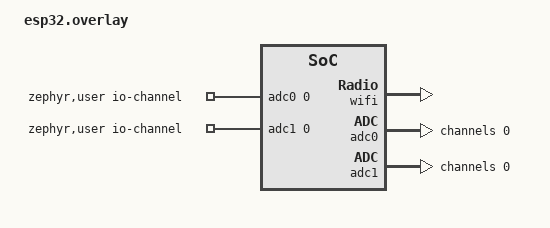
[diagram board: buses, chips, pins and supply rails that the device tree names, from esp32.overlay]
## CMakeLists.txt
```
# SPDX-License-Identifier: Apache-2.0

cmake_minimum_required(VERSION 3.20.0)
find_package(Zephyr REQUIRED HINTS $ENV{ZEPHYR_BASE})
project(smart_parking_demo)

FILE(GLOB app_sources src/*.cpp)
target_sources(app PRIVATE ${app_sources})
```

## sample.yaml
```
sample:
  name: Demo for Smart Parking Sensor
```

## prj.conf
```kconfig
CONFIG_STDOUT_CONSOLE=y
CONFIG_PRINTK=y

# Use DHCP for IPv4
CONFIG_NET_DHCPV4=y
CONFIG_NET_CONFIG_AUTO_INIT=y

CONFIG_I2C=y
CONFIG_ADC=y

CONFIG_WIFI=y
CONFIG_WIFI_ESP32=y
#CONFIG_HEAP_MEM_POOL_SIZE=96304
CONFIG_INIT_STACKS=y

CONFIG_NET_ARP=y

CONFIG_NETWORKING=y
CONFIG_NET_IPV4=y
CONFIG_NET_IPV6=n
CONFIG_NET_TCP=y

#UDP enabled to fix: [error: 'struct net_if_config' has no member named 'dhcpv4']
CONFIG_NET_UDP=y
#CONFIG_DNS_RESOLVER=y
#CONFIG_DNS_RESOLVER_AI_MAX_ENTRIES=10
CONFIG_NET_SOCKETS=y
#CONFIG_HTTP_CLIENT=y
CONFIG_NET_SOCKETS_POSIX_NAMES=y
CONFIG_NET_SOCKETS_POLL_MAX=4
CONFIG_NET_CONNECTION_MANAGER=y

CONFIG_NET_STATISTICS=y
CONFIG_NET_STATISTICS_PERIODIC_OUTPUT=y


## Or assign a static IP address (useful for testing)
## Following line must be enabled, otherwise WiFi connection fails with -1.
CONFIG_NET_CONFIG_SETTINGS=y
#
#

# Enabling logging can be helpful for debugging
CONFIG_NET_LOG=y
CONFIG_NET_SHELL=n
CONFIG_WIFI_LOG_LEVEL_ERR=y


CONFIG_NET_TX_STACK_SIZE=2048
CONFIG_NET_RX_STACK_SIZE=2048

CONFIG_NET_PKT_RX_COUNT=10
CONFIG_NET_PKT_TX_COUNT=10

CONFIG_NET_BUF_RX_COUNT=20
CONFIG_NET_BUF_TX_COUNT=20

CONFIG_NET_MAX_CONTEXTS=10

# Added to prevent error with missing #include <ethernet/eth_stats.h> for esp_wifi_drv.c
# Adding this line will cause CMAKE Warning: No SOURCES given to Zephyr library: drivers__ethernet
# Just ignore.
CONFIG_NET_L2_ETHERNET=y


CONFIG_NET_MGMT=n
CONFIG_NET_MGMT_EVENT=n
CONFIG_NET_MGMT_EVENT_INFO=n
CONFIG_NET_DEBUG_MGMT_EVENT_STACK=n
CONFIG_NET_L2_WIFI_MGMT=n
CONFIG_NET_STATISTICS_WIFI=n

#Net application
CONFIG_NET_TCP=y
CONFIG_NET_IPV4=y
CONFIG_NET_LOG=n
CONFIG_NET_STATISTICS=n






#
#
#
#CONFIG_EARLY_CONSOLE=y
#
#CONFIG_NETWORKING=y
#CONFIG_TEST_RANDOM_GENERATOR=y
#
#CONFIG_NET_TX_STACK_SIZE=2048
#CONFIG_NET_RX_STACK_SIZE=2048
#
#CONFIG_NET_PKT_RX_COUNT=10
#CONFIG_NET_PKT_TX_COUNT=10
#CONFIG_NET_BUF_RX_COUNT=20
#CONFIG_NET_BUF_TX_COUNT=20
#CONFIG_NET_MAX_CONTEXTS=10
#CONFIG_NET_DHCPV4=y
#
#CONFIG_NET_IPV4=y
#CONFIG_NET_IPV6=n
#
#CONFIG_NET_TCP=y
#
#CONFIG_NET_LOG=y
#CONFIG_INIT_STACKS=y
#
#CONFIG_NET_SHELL=y
#
#CONFIG_NET_STATISTICS=y
#CONFIG_NET_STATISTICS_PERIODIC_OUTPUT=n
#
#CONFIG_WIFI=y
#CONFIG_WIFI_LOG_LEVEL_ERR=y
#CONFIG_NET_L2_WIFI_SHELL=y



CONFIG_NETWORKING=y
CONFIG_NET_IPV4=y
CONFIG_NET_ARP=y
CONFIG_NET_DHCPV4=y

#CONFIG_TEST_RANDOM_GENERATOR=y

CONFIG_LOG=y

CONFIG_SLIP_STATISTICS=n
#CONFIG_NET_SHELL=y


#cpp
CONFIG_CPP=y
CONFIG_CPLUSPLUS=y
CONFIG_LIB_CPLUSPLUS=y
#CONFIG_CPP_MAIN=y
#CONFIG_GLIBCXX_LIBCPP=y
#CONFIG_LIBCPP_IMPLEMENTATION=y

#SNTP
CONFIG_SNTP=y
#CONFIG_POSIX_API=y

CONFIG_MAIN_STACK_SIZE=2048

# debug
```

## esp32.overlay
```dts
/*
 * Copyright (c) 2022 Wolter HV <wolterhv@gmx.de>
 *
 * SPDX-License-Identifier: Apache-2.0
 */

&wifi {
	status = "okay";
};

/ {
	zephyr,user {
		io-channels =
			<&adc0 0>,
			<&adc1 0>;
	};
};

&adc0 {
	status = "okay";
	#address-cells = <1>;
	#size-cells = <0>;

	channel@0 {
		reg = <0>;
		zephyr,gain = "ADC_GAIN_1_4";
		zephyr,reference = "ADC_REF_INTERNAL";
		zephyr,acquisition-time = <ADC_ACQ_TIME_DEFAULT>;
		zephyr,resolution = <12>;
	};
};

&adc1 {
	status = "okay";
	#address-cells = <1>;
	#size-cells = <0>;

	channel@0 {
		reg = <0>;
		zephyr,gain = "ADC_GAIN_1_4";
		zephyr,reference = "ADC_REF_INTERNAL";
		zephyr,acquisition-time = <ADC_ACQ_TIME_DEFAULT>;
		zephyr,resolution = <12>;
	};
};
```

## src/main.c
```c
/*
 * Copyright (c) 2015 Intel Corporation
 *
 * SPDX-License-Identifier: Apache-2.0
 */

#include <errno.h>
#include <zephyr/kernel.h>
#include <zephyr/sys/printk.h>
#include <zephyr/device.h>
#include <zephyr/drivers/i2c.h>

// WiFi stuff
#include <zephyr/net/net_mgmt.h>
#include <zephyr/net/net_if.h>
#include <zephyr/net/wifi_mgmt.h>
#include <zephyr/net/net_event.h>

// TCP
#include <zephyr/net/net_ip.h>
#include <zephyr/net/socket.h>
#include <zephyr/net/websocket.h>

//
#include "hmc_5883l_driver_port.h"

static bool flagIP = false;


/**
 * 
 * Socket stuff
*/

static int setup_socket(sa_family_t family, const char *server, int port,
			int *sock, struct sockaddr *addr, socklen_t addr_len)
{
	const char *family_str = "IPv4";
	int ret = 0;

	memset(addr, 0, addr_len);

    net_sin(addr)->sin_family = AF_INET;
    net_sin(addr)->sin_port = htons(port);
    inet_pton(AF_INET, server, &net_sin(addr)->sin_addr);

    *sock = socket(AF_INET, SOCK_STREAM, IPPROTO_TCP);

	if (*sock < 0) {
		printk("Failed to create %s HTTP socket (%d)", family_str,
			-errno);
	}
    else
    {
        printk("Socket successfully created.\n");
    }

	return ret;
}

static int connect_socket(sa_family_t family, const char *server, int port,
			  int *sock, struct sockaddr *addr, socklen_t addr_len)
{
	int ret;

	ret = setup_socket(family, server, port, sock, addr, addr_len);
	if (ret < 0 || *sock < 0) {
		return -1;
	}

    printk("Connecting...\n");
	ret = connect(*sock, addr, addr_len);
    printk("Done!\n");
	if (ret < 0) {
		printk("Cannot connect to %s remote (%d)\n",
			"IPv4",
			-errno);
		ret = -errno;
	}
    else
    {
        printk("Socket connected.\n");
    }

	return ret;
}

static int connect_cb(int sock, struct http_request *req, void *user_data)
{
	printk("Websocket %d for %s connected.", sock, (char *)user_data);

	return 0;
}


/**
 * @file Sample app using the Fujitsu MB85RC256V FRAM through I2C.
 */

/* Macros ========================================================*/
/* WiFi parameters */
#define AP_SSID_ "Funeswifi"
#define AP_PSK_ "00435763252"

/* size of stack area used by each thread */
#define STACKSIZE 1024

/* scheduling priority used by each thread */
#define PRIORITY 7

/* Private functions =============================================*/
static K_SEM_DEFINE(wifi_connected, 0, 1);
static K_SEM_DEFINE(ipv4_address_obtained, 0, 1);

static struct net_mgmt_event_callback wifi_cb;
static struct net_mgmt_event_callback ipv4_cb;

static void handle_wifi_connect_result(struct net_mgmt_event_callback *cb)
{
    const struct wifi_status *status = (const struct wifi_status *)cb->info;

    if (status->status)
    {
        printk("Connection request failed (%d)\n", status->status);
    }
    else
    {
        printk("Connected\n");
        //k_sem_give(&wifi_connected);
    }
}

static void handle_wifi_disconnect_result(struct net_mgmt_event_callback *cb)
{
    const struct wifi_status *status = (const struct wifi_status *)cb->info;

    if (status->status)
    {
        printk("Disconnection request (%d)\n", status->status);
    }
}

static void handle_ipv4_result(struct net_if *iface)
{
    int i = 0;

    for (i = 0; i < NET_IF_MAX_IPV4_ADDR; i++) {

        char buf[NET_IPV4_ADDR_LEN];

        if (iface->config.ip.ipv4->unicast[i].addr_type != NET_ADDR_DHCP) {
            continue;
        }

        printk("IPv4 address: %s\n",
                net_addr_ntop(AF_INET,
                                &iface->config.ip.ipv4->unicast[i].address.in_addr,
                                buf, sizeof(buf)));
        printk("Subnet: %s\n",
                net_addr_ntop(AF_INET,
                                &iface->config.ip.ipv4->netmask,
                                buf, sizeof(buf)));
        printk("Router: %s\n",
                net_addr_ntop(AF_INET,
                                &iface->config.ip.ipv4->gw,
                                buf, sizeof(buf)));
        }

        //k_sem_give(&ipv4_address_obtained);
        flagIP = true;
}

static void wifi_mgmt_event_handler(struct net_mgmt_event_callback *cb, uint32_t mgmt_event, struct net_if *iface)
{
    switch (mgmt_event)
    {

        case NET_EVENT_WIFI_CONNECT_RESULT:
            printk("Received NET_EVENT_WIFI_CONNECT_RESULT.\n");
            handle_wifi_connect_result(cb);
            break;

        case NET_EVENT_WIFI_DISCONNECT_RESULT:
            printk("Received NET_EVENT_WIFI_DISCONNECT_RESULT.\n");
            handle_wifi_disconnect_result(cb);
            break;

        case NET_EVENT_IPV4_ADDR_ADD:
            printk("Received NET_EVENT_IPV4_ADDR_ADD.\n");
            handle_ipv4_result(iface);
            break;

        default:
            break;
    }
}

void wifi_connect(void)
{
    struct net_if *iface = net_if_get_default();

    struct wifi_connect_req_params wifi_params = {0};

    wifi_params.ssid = AP_SSID_;
    wifi_params.psk = AP_PSK_;
    wifi_params.ssid_length = strlen(AP_SSID_);
    wifi_params.psk_length = strlen(AP_PSK_);
    wifi_params.channel = WIFI_CHANNEL_ANY;
    wifi_params.security = WIFI_SECURITY_TYPE_PSK;
    wifi_params.band = WIFI_FREQ_BAND_2_4_GHZ; 
    wifi_params.mfp = WIFI_MFP_DISABLE;
    wifi_params.timeout = SYS_FOREVER_MS;

    printk("Connecting to SSID: %s\n", wifi_params.ssid);

    if (net_mgmt(NET_REQUEST_WIFI_AP_DISABLE, iface, &wifi_params, sizeof(struct wifi_connect_req_params)))
    {
       printk("WiFi in AP Mode Disable Error.\n");
    }
    else
    {
       printk("WiFi in AP Mode Disable.\n");
    }

    if (net_mgmt(NET_REQUEST_WIFI_SCAN, iface, &wifi_params, sizeof(struct wifi_connect_req_params)))
    {
       printk("WiFi Scan Request Error.\n");
    }
    else
    {
       printk("WiFi Scan Request Done!.\n");
    }

    if (net_mgmt_event_wait_on_iface(iface, NET_EVENT_WIFI_SCAN_RESULT, NULL, NULL, NULL, K_FOREVER))
        printk("Scan done!\n");

    if (net_mgmt(NET_REQUEST_WIFI_CONNECT, iface, &wifi_params, sizeof(struct wifi_connect_req_params)))
    {
        printk("WiFi Connection Request Failed\n");
    }
	else
	{
		printk("WiFi Connection Request success.\n");
	}

#if 0
    if (net_mgmt_event_wait_on_iface(iface, NET_EVENT_WIFI_CONNECT_RESULT, NULL, NULL, NULL, K_FOREVER))
        printk("WiFi connected.\n");
#endif
}

void wifi_status(void)
{
    struct net_if *iface = net_if_get_default();

    struct wifi_iface_status status = {0};

    if (net_mgmt(NET_REQUEST_WIFI_IFACE_STATUS, iface, &status,	sizeof(struct wifi_iface_status)))
    {
        printk("WiFi Status Request Failed\n");
    }
    else
    {
        printk("WiFi Status Request Success.\n");
    }

    printk("\n");

    if (status.state >= WIFI_STATE_ASSOCIATED) {
        printk("SSID: %-32s\n", status.ssid);
        printk("Band: %s\n", wifi_band_txt(status.band));
        printk("Channel: %d\n", status.channel);
        printk("Security: %s\n", wifi_security_txt(status.security));
        printk("RSSI: %d\n", status.rssi);
    }
}

void wifi_disconnect(void)
{
    struct net_if *iface = net_if_get_default();

    if (net_mgmt(NET_REQUEST_WIFI_DISCONNECT, iface, NULL, 0))
    {
        printk("WiFi Disconnection Request Failed\n");
    }
}
/* Threads =======================================================*/

static void hmc_thread(void)
{
	const struct device *const i2c_dev = DEVICE_DT_GET(DT_NODELABEL(i2c0));
    hmc_5883l_driver_t hmc_driver;
	uint8_t hmc_buf[20];
	uint8_t ret;
	uint8_t command[2] = {0x06, 0x03};

    // Driver initialization
    hmc_5883l_driverInitPort(&hmc_driver, i2c_dev);
	hmc_configureContinuosMode(&hmc_driver);

	for(;;)
	{
		int16_t xx, yy, zz;
		uint8_t cmd;
		k_msleep(100);

		cmd=3;
		ret = hmc_driver.write(&hmc_driver, &cmd, 1);
		if (ret)
			printk("Error on write Mode.");
		ret = hmc_driver.read(&hmc_driver, &hmc_buf[3], 3);
		if (ret)
			printk("Error on write 1st command.\r\n");
		cmd=6;
		ret = hmc_driver.write(&hmc_driver, &cmd, 1);
		if (ret)
			printk("Error on write Mode.");
		ret = hmc_driver.read(&hmc_driver, &hmc_buf[6], 3);
		if (ret)
			printk("Error on write 1st command.\r\n");
		cmd=9;
		ret = hmc_driver.write(&hmc_driver, &cmd, 1);
		if (ret)
			printk("Error on write Mode.");
		ret = hmc_driver.read(&hmc_driver, &hmc_buf[9], 4);
		if (ret)
			printk("Error on write 1st command.\r\n");

		xx = hmc_buf[3] << 8 | hmc_buf[4];
		zz = hmc_buf[5] << 8 | hmc_buf[6];
		yy = hmc_buf[7] << 8 | hmc_buf[8];

		printk("x:(%i) y:(%i) z:(%i) status:(%x)\r\n", xx, yy, zz, hmc_buf[9]);
		printk("idA:(%x) idB:(%x) idC:(%x)", hmc_buf[10], hmc_buf[11], hmc_buf[12]);
	}

#if 0
	hmc_buf[0] = 9;
	ret = hmc_driver.write(&hmc_driver, hmc_buf, 1);
	if (ret)
	{
		printk("Error on 1st write.");
	}

	ret = hmc_driver.read(&hmc_driver, hmc_buf, 4);
	if (ret)
	{
		printk("Error on 1st write.");
	}
	else
	{
		printk("Successfully read all bytes:\r\n");
		for( uint8_t i=0; i<4; ++i)
		{
			printk("field[%d]: (0x%x)\r\n", i, hmc_buf[i]);
		}
	}
#endif
}

static struct net_mgmt_event_callback mgmt_cb;

static void handler(struct net_mgmt_event_callback *cb,
		    uint32_t mgmt_event,
		    struct net_if *iface)
{
	int i = 0;

	if (mgmt_event != NET_EVENT_IPV4_ADDR_ADD) {
		return;
	}

	for (i = 0; i < NET_IF_MAX_IPV4_ADDR; i++) {
		char buf[NET_IPV4_ADDR_LEN];

		if (iface->config.ip.ipv4->unicast[i].addr_type !=
							NET_ADDR_DHCP) {
			continue;
		}

		printk("Your address: %s",
			net_addr_ntop(AF_INET,
			    &iface->config.ip.ipv4->unicast[i].address.in_addr,
						  buf, sizeof(buf)));
		printk("Lease time: %u seconds",
			 iface->config.dhcpv4.lease_time);
		printk("Subnet: %s",
			net_addr_ntop(AF_INET,
				       &iface->config.ip.ipv4->netmask,
				       buf, sizeof(buf)));
		printk("Router: %s",
			net_addr_ntop(AF_INET,
						 &iface->config.ip.ipv4->gw,
						 buf, sizeof(buf)));
	}
}


void main(void)
{
	int sock;

    printk("WiFi Example\n\n");

    net_mgmt_init_event_callback(&wifi_cb, wifi_mgmt_event_handler,
                                 NET_EVENT_WIFI_CONNECT_RESULT | NET_EVENT_WIFI_DISCONNECT_RESULT);

    net_mgmt_init_event_callback(&ipv4_cb, wifi_mgmt_event_handler, NET_EVENT_IPV4_ADDR_ADD);

    net_mgmt_add_event_callback(&wifi_cb);
    net_mgmt_add_event_callback(&ipv4_cb);
    printk("Callbacks set.\n");

    k_sleep(K_SECONDS(2)); 
    wifi_connect();
    printk("Connection Done...\n");
    //k_sem_take(&wifi_connected, K_FOREVER);
    printk("2Connection Done...\n");
    //k_sem_take(&ipv4_address_obtained, K_FOREVER);
    printk("Ready...\n\n");

    while(!flagIP) k_sleep(K_SECONDS(1));

	#if 0
    printk("Looking up IP addresses:\n");
    struct zsock_addrinfo *res;
    nslookup("iot.beyondlogic.org", &res);
    print_addrinfo_results(&res);

    printk("Connecting to HTTP Server:\n");
    sock = connect_socket(&res);
    http_get(sock, "iot.beyondlogic.org", "/test.txt");
    zsock_close(sock);
    
    wifi_connect();
    // Stay connected for 30 seconds, then disconnect.
	#endif

    while(1)
    {
        // Socket stuff

        int sock4 = -1;
        int websock4 = -1;
        struct sockaddr_in addr4;
        size_t amount;
        int ret;

        (void)connect_socket(AF_INET, "169.55.61.243", 9012,
                        &sock4, (struct sockaddr *)&addr4,
                        sizeof(addr4));
        if (sock4 < 0) {
            printk("Cannot create HTTP connection.");
        }
        else
        {
            printk("Connection created.\n");

            printk("Sending...\n");

            char data[] = "ESP32/1.0|POST|BBFF-DQaxQtnjWZzKDzTsVRtOUfNLulXxqf|64a2425cbe387b5d626506e1:pythonTestDevice=>fieldX:20.2|end";

            int rc = send(sock4, data, strlen(data), 0);

            printk("Data sent!\n");
            
            if (rc < 0)
                printk("Error sending.\n");
            
            close(sock4);
        }

        k_sleep(K_MINUTES(10));
    }
#if 0
    wifi_disconnect();
    while(1)
    {
        printk("Looping...\r\n");
        k_sleep(K_SECONDS(5)); 
        wifi_status();
    }
    #endif
}

#if 0
K_THREAD_DEFINE(hmc_id, STACKSIZE, hmc_thread, NULL, NULL, NULL,
		PRIORITY, 0, 0);
        #endif
```

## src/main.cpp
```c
/*
 * Copyright (c) 2015 Intel Corporation
 *
 * SPDX-License-Identifier: Apache-2.0
 */
#include <errno.h>
#include <zephyr/kernel.h>
#include <zephyr/sys/printk.h>
#include <zephyr/device.h>
#include <zephyr/drivers/i2c.h>
#include <zephyr/drivers/adc.h>

// WiFi stuff
#include <zephyr/net/net_mgmt.h>
#include <zephyr/net/net_if.h>
#include <zephyr/net/wifi_mgmt.h>
#include <zephyr/net/net_event.h>

// TCP
#include <zephyr/net/net_ip.h>
#include <zephyr/net/socket.h>
#include <zephyr/net/websocket.h>
#include "esp_sleep.h"

// SNTP
#include <zephyr/net/sntp.h>
#ifdef CONFIG_POSIX_API
#include <arpa/inet.h>
#endif

#include <zephyr/posix/time.h>

//
#include "hmc_5883l_driver_port.h"

// CPP
#include <iostream>
#include <string>

// Power Management
#include <zephyr/pm/pm.h>
#include <zephyr/pm/device.h>
#include <zephyr/pm/policy.h>

static bool flagIP = false;

struct hmc_values_s
{
   int x;
   int y;
   int z;
   int sample = 123; 
};

typedef struct hmc_values_s hmc_values_t;
static hmc_values_t hmc_values;

K_SEM_DEFINE(hmc_sem, 0, K_SEM_MAX_LIMIT);
K_SEM_DEFINE(wifi_sem, 0, K_SEM_MAX_LIMIT);


/**
 * 
 * Socket stuff
*/

static int setup_socket(sa_family_t family, const char *server, int port,
			int *sock, struct sockaddr *addr, socklen_t addr_len)
{
	const char *family_str = "IPv4";
	int ret = 0;

	memset(addr, 0, addr_len);

    net_sin(addr)->sin_family = AF_INET;
    net_sin(addr)->sin_port = htons(port);
    inet_pton(AF_INET, server, &net_sin(addr)->sin_addr);

    *sock = socket(AF_INET, SOCK_STREAM, IPPROTO_TCP);

	if (*sock < 0) {
		printk("Failed to create %s HTTP socket (%d)", family_str,
			-errno);
	}
    else
    {
        printk("Socket successfully created.\n");
    }

	return ret;
}

static int connect_socket(sa_family_t family, const char *server, int port,
			  int *sock, struct sockaddr *addr, socklen_t addr_len)
{
	int ret;

	ret = setup_socket(family, server, port, sock, addr, addr_len);
	if (ret < 0 || *sock < 0) {
		return -1;
	}

    printk("Connecting...\n");
	ret = connect(*sock, addr, addr_len);
    printk("Done!\n");
	if (ret < 0) {
		printk("Cannot connect to %s remote (%d)\n",
			"IPv4",
			-errno);
		ret = -errno;
	}
    else
    {
        printk("Socket connected.\n");
    }

	return ret;
}

static int connect_cb(int sock, struct http_request *req, void *user_data)
{
	printk("Websocket %d for %s connected.", sock, (char *)user_data);

	return 0;
}


/**
 * @file Sample app using the Fujitsu MB85RC256V FRAM through I2C.
 */

/* Macros ========================================================*/
/* WiFi parameters */
#define AP_SSID_ "Funeswifi"
#define AP_PSK_ "00435763252"

/* size of stack area used by each thread */
#define STACKSIZE 2048

/* scheduling priority used by each thread */
#define PRIORITY 7

/* Private functions =============================================*/
static K_SEM_DEFINE(wifi_connected, 0, 1);
static K_SEM_DEFINE(ipv4_address_obtained, 0, 1);

static struct net_mgmt_event_callback wifi_cb;
static struct net_mgmt_event_callback ipv4_cb;

static void handle_wifi_connect_result(struct net_mgmt_event_callback *cb)
{
    const struct wifi_status *status = (const struct wifi_status *)cb->info;

    if (status->status)
    {
        printk("Connection request failed (%d)\n", status->status);
    }
    else
    {
        printk("Connected\n");
        //k_sem_give(&wifi_connected);
    }
}

static void handle_wifi_disconnect_result(struct net_mgmt_event_callback *cb)
{
    const struct wifi_status *status = (const struct wifi_status *)cb->info;

    if (status->status)
    {
        printk("Disconnection request (%d)\n", status->status);
    }
}

static void handle_ipv4_result(struct net_if *iface)
{
    int i = 0;

    for (i = 0; i < NET_IF_MAX_IPV4_ADDR; i++) {

        char buf[NET_IPV4_ADDR_LEN];

        if (iface->config.ip.ipv4->unicast[i].addr_type != NET_ADDR_DHCP) {
            continue;
        }

        printk("IPv4 address: %s\n",
                net_addr_ntop(AF_INET,
                                &iface->config.ip.ipv4->unicast[i].address.in_addr,
                                buf, sizeof(buf)));
        printk("Subnet: %s\n",
                net_addr_ntop(AF_INET,
                                &iface->config.ip.ipv4->netmask,
                                buf, sizeof(buf)));
        printk("Router: %s\n",
                net_addr_ntop(AF_INET,
                                &iface->config.ip.ipv4->gw,
                                buf, sizeof(buf)));
        }

        //k_sem_give(&ipv4_address_obtained);
        flagIP = true;
}

static void wifi_mgmt_event_handler(struct net_mgmt_event_callback *cb, uint32_t mgmt_event, struct net_if *iface)
{
    switch (mgmt_event)
    {

        case NET_EVENT_WIFI_CONNECT_RESULT:
            printk("Received NET_EVENT_WIFI_CONNECT_RESULT.\n");
            handle_wifi_connect_result(cb);
            break;

        case NET_EVENT_WIFI_DISCONNECT_RESULT:
            printk("Received NET_EVENT_WIFI_DISCONNECT_RESULT.\n");
            handle_wifi_disconnect_result(cb);
            break;

        case NET_EVENT_IPV4_ADDR_ADD:
            printk("Received NET_EVENT_IPV4_ADDR_ADD.\n");
            handle_ipv4_result(iface);
            break;

        default:
            break;
    }
}

void wifi_connect(void)
{
    struct net_if *iface = net_if_get_default();

    struct wifi_connect_req_params wifi_params = {0};

    wifi_params.ssid = reinterpret_cast<uint8_t *>(const_cast<char*>(AP_SSID_));
    wifi_params.psk = reinterpret_cast<uint8_t*>(const_cast<char*>(AP_PSK_));
    wifi_params.ssid_length = strlen(AP_SSID_);
    wifi_params.psk_length = strlen(AP_PSK_);
    wifi_params.channel = WIFI_CHANNEL_ANY;
    wifi_params.security = WIFI_SECURITY_TYPE_PSK;
    wifi_params.band = WIFI_FREQ_BAND_2_4_GHZ; 
    wifi_params.mfp = WIFI_MFP_DISABLE;
    wifi_params.timeout = SYS_FOREVER_MS;

    printk("Connecting to SSID: %s\n", wifi_params.ssid);

    if (net_mgmt(NET_REQUEST_WIFI_AP_DISABLE, iface, &wifi_params, sizeof(struct wifi_connect_req_params)))
    {
       printk("WiFi in AP Mode Disable Error.\n");
    }
    else
    {
       printk("WiFi in AP Mode Disable.\n");
    }

    if (net_mgmt(NET_REQUEST_WIFI_SCAN, iface, &wifi_params, sizeof(struct wifi_connect_req_params)))
    {
       printk("WiFi Scan Request Error.\n");
    }
    else
    {
       printk("WiFi Scan Request Done!.\n");
    }

    if (net_mgmt_event_wait_on_iface(iface, NET_EVENT_WIFI_SCAN_RESULT, NULL, NULL, NULL, K_FOREVER))
        printk("Scan done!\n");

    if (net_mgmt(NET_REQUEST_WIFI_CONNECT, iface, &wifi_params, sizeof(struct wifi_connect_req_params)))
    {
        printk("WiFi Connection Request Failed\n");
    }
	else
	{
		printk("WiFi Connection Request success.\n");
	}

#if 0
    if (net_mgmt_event_wait_on_iface(iface, NET_EVENT_WIFI_CONNECT_RESULT, NULL, NULL, NULL, K_FOREVER))
        printk("WiFi connected.\n");
#endif
}

void wifi_status(void)
{
    struct net_if *iface = net_if_get_default();

    struct wifi_iface_status status = {0};

    if (net_mgmt(NET_REQUEST_WIFI_IFACE_STATUS, iface, &status,	sizeof(struct wifi_iface_status)))
    {
        printk("WiFi Status Request Failed\n");
    }
    else
    {
        printk("WiFi Status Request Success.\n");
    }

    printk("\n");

    if (status.state >= WIFI_STATE_ASSOCIATED) {
        printk("SSID: %-32s\n", status.ssid);
        printk("Band: %s\n", wifi_band_txt(status.band));
        printk("Channel: %d\n", status.channel);
        printk("Security: %s\n", wifi_security_txt(status.security));
        printk("RSSI: %d\n", status.rssi);
    }
}

void wifi_disconnect(void)
{
    struct net_if *iface = net_if_get_default();

    if (net_mgmt(NET_REQUEST_WIFI_DISCONNECT, iface, NULL, 0))
    {
        printk("WiFi Disconnection Request Failed\n");
    }
}
/* Threads =======================================================*/

extern "C"
{

static void hmc_thread(void)
{
    std::cout << "Running thread...\n";
	const struct device *const i2c_dev = DEVICE_DT_GET(DT_NODELABEL(i2c0));
    hmc_5883l_driver_t hmc_driver;
	uint8_t hmc_buf[20];
	uint8_t ret;
	uint8_t command[2] = {0x06, 0x03};


    // Driver initialization
    hmc_5883l_driverInitPort(&hmc_driver, i2c_dev);
	hmc_configureContinuosMode(&hmc_driver);

	for(;;)
	{
        std::cout << "hmc\r\n";
		int16_t xx, yy, zz;
		uint8_t cmd;
		k_msleep(100);

		cmd=3;
		ret = hmc_driver.write(&hmc_driver, &cmd, 1);
		if (ret)
			printk("Error on write Mode.");
		ret = hmc_driver.read(&hmc_driver, &hmc_buf[3], 3);
		if (ret)
			printk("Error on write 1st command.\r\n");
		cmd=6;
		ret = hmc_driver.write(&hmc_driver, &cmd, 1);
		if (ret)
			printk("Error on write Mode.");
		ret = hmc_driver.read(&hmc_driver, &hmc_buf[6], 3);
		if (ret)
			printk("Error on write 1st command.\r\n");
		cmd=9;
		ret = hmc_driver.write(&hmc_driver, &cmd, 1);
		if (ret)
			printk("Error on write Mode.");
		ret = hmc_driver.read(&hmc_driver, &hmc_buf[9], 4);
		if (ret)
			printk("Error on write 1st command.\r\n");

		xx = hmc_buf[3] << 8 | hmc_buf[4];
		zz = hmc_buf[5] << 8 | hmc_buf[6];
		yy = hmc_buf[7] << 8 | hmc_buf[8];

        hmc_values.x = xx;
        hmc_values.y = yy;
        hmc_values.z = zz;
        //k_sem_give(&hmc_sem);
  //      k_sem_take(&wifi_sem, K_FOREVER);

		//printk("x:(%i) y:(%i) z:(%i) status:(%x)\r\n", xx, yy, zz, hmc_buf[9]);
		//printk("idA:(%x) idB:(%x) idC:(%x)\r\n", hmc_buf[10], hmc_buf[11], hmc_buf[12]);
	}

#if 0
	hmc_buf[0] = 9;
	ret = hmc_driver.write(&hmc_driver, hmc_buf, 1);
	if (ret)
	{
		printk("Error on 1st write.");
	}

	ret = hmc_driver.read(&hmc_driver, hmc_buf, 4);
	if (ret)
	{
		printk("Error on 1st write.");
	}
	else
	{
		printk("Successfully read all bytes:\r\n");
		for( uint8_t i=0; i<4; ++i)
		{
			printk("field[%d]: (0x%x)\r\n", i, hmc_buf[i]);
		}
	}
#endif
}
}

static struct net_mgmt_event_callback mgmt_cb;

static void handler(struct net_mgmt_event_callback *cb,
		    uint32_t mgmt_event,
		    struct net_if *iface)
{
	int i = 0;

	if (mgmt_event != NET_EVENT_IPV4_ADDR_ADD) {
		return;
	}

	for (i = 0; i < NET_IF_MAX_IPV4_ADDR; i++) {
		char buf[NET_IPV4_ADDR_LEN];

		if (iface->config.ip.ipv4->unicast[i].addr_type !=
							NET_ADDR_DHCP) {
			continue;
		}

		printk("Your address: %s",
			net_addr_ntop(AF_INET,
			    &iface->config.ip.ipv4->unicast[i].address.in_addr,
						  buf, sizeof(buf)));
		printk("Lease time: %u seconds",
			 iface->config.dhcpv4.lease_time);
		printk("Subnet: %s",
			net_addr_ntop(AF_INET,
				       &iface->config.ip.ipv4->netmask,
				       buf, sizeof(buf)));
		printk("Router: %s",
			net_addr_ntop(AF_INET,
						 &iface->config.ip.ipv4->gw,
						 buf, sizeof(buf)));
	}
}

#define WAKEUP_TIME_SEC		(20)

int main(void)
{
    return 0;
}

void wifi_thread(void)
{
    k_sleep(K_SECONDS(10)); 
	int sock;
    std::cout << "WiFi Example\n\n";

    net_mgmt_init_event_callback(&wifi_cb, wifi_mgmt_event_handler,
                                 NET_EVENT_WIFI_CONNECT_RESULT | NET_EVENT_WIFI_DISCONNECT_RESULT);

    net_mgmt_init_event_callback(&ipv4_cb, wifi_mgmt_event_handler, NET_EVENT_IPV4_ADDR_ADD);

    net_mgmt_add_event_callback(&wifi_cb);
    net_mgmt_add_event_callback(&ipv4_cb);
    std::cout << "Callbacks\n";

    k_sleep(K_SECONDS(2)); 
    wifi_connect();
    std::cout << "Ready...\n\n";

    while(!flagIP) k_sleep(K_SECONDS(1));

    //SNTP-----------------------
    struct sntp_ctx ctx;
    struct sockaddr_in addr;
    struct sntp_time sntp_time;
    int rv;
    struct timeval tv;
    struct timespec ts;

    /* ipv4 */
    memset(&addr, 0, sizeof(addr));
    addr.sin_family = AF_INET;
    addr.sin_port = htons(123);
    zsock_inet_pton(AF_INET, "170.210.222.10", &addr.sin_addr);

    rv = sntp_init(&ctx, (struct sockaddr *) &addr,
               sizeof(struct sockaddr_in));
    if (rv < 0) {
        std::cout << "Failed to init SNTP IPv4\r\n";
    }

    std::cout << "Sending SNTP IPv4 request...\r\n";
    rv = sntp_query(&ctx, 4 * MSEC_PER_SEC, &sntp_time);
    if (rv < 0) {
        std::cout << "SNTP IPv4 request failed: " << rv << "\r\n";
    }


    std::cout << "status: " << rv << "\r\n";
    printk("time since Epoch: high word: %u, low word: %u",
        (uint32_t)(sntp_time.seconds >> 32), (uint32_t)sntp_time.seconds);

    ts.tv_sec = sntp_time.seconds;

    //-----------------------SNTP


    while(1)
    {
        printk("WiFi\r\n\n");
        // Socket stuff
        int sock4 = -1;
        int websock4 = -1;
        struct sockaddr_in addr4;
        size_t amount;
        int ret;

        (void)connect_socket(AF_INET, "169.55.61.243", 9012,
                        &sock4, (struct sockaddr *)&addr4,
                        sizeof(addr4));
        if (sock4 < 0) {
            printk("Cannot create HTTP connection.");
        }
        else
        {
            printk("Connection created.\n");

            printk("Sending...\n");

            std::string log_str = "Logging from cpp.";
            printk("%s",log_str.c_str());

            std::cout << "Converting...\r\n";
            std::string xdata = "fieldX:" + std::to_string(hmc_values.x);
            std::string ydata = "fieldY:" + std::to_string(hmc_values.y);
            std::string zdata = "fieldZ:" + std::to_string(hmc_values.z);
            std::cout << "Convertion done!\r\n";
            std::string data = "ESP32/1.0|POST|BBFF-DQaxQtnjWZzKDzTsVRtOUfNLulXxqf|64a2425cbe387b5d626506e1:pythonTestDevice=>"+xdata+","+ydata+","+zdata+"|end";

            int rc = send(sock4, data.c_str(), strlen(data.c_str()), 0);

            printk("Data sent!\n");
            
            if (rc < 0)
                printk("Error sending.\n");

#if 1
            std::cout << "Converting...\r\n";
            std::string timestamp_str = "time: " + std::to_string(ts.tv_sec + k_uptime_get()/1000);
            std::cout << "Convertion Done\r\n";
            std::cout << timestamp_str << std::endl;
#endif
            
            close(sock4);
            //k_sem_give(&wifi_sem);
            //k_sem_take(&hmc_sem, K_FOREVER);
        }

        //k_sleep(K_MINUTES(1));
        k_sleep(K_SECONDS(5));
    }
#if 0
    wifi_disconnect();
    while(1)
    {
        printk("Looping...\r\n");
        k_sleep(K_SECONDS(5)); 
        wifi_status();
    }
    #endif
}

// ADC stuff ======================================

#define DT_SPEC_AND_COMMA(node_id, prop, idx) \
	ADC_DT_SPEC_GET_BY_IDX(node_id, idx),

/* Data of ADC io-channels specified in devicetree. */
static const struct adc_dt_spec adc_channels[] = {
	DT_FOREACH_PROP_ELEM(DT_PATH(zephyr_user), io_channels,
			     DT_SPEC_AND_COMMA)
};

void adc_thread(void)
{
	int err;
	uint32_t count = 0;
	uint16_t buf;
	struct adc_sequence sequence = {
		.buffer = &buf,
		/* buffer size in bytes, not number of samples */
		.buffer_size = sizeof(buf),
	};

	/* Configure channels individually prior to sampling. */
	for (size_t i = 0U; i < ARRAY_SIZE(adc_channels); i++) {
		if (!device_is_ready(adc_channels[i].dev)) {
			printk("ADC controller device %s not ready\n", adc_channels[i].dev->name);
		}

		err = adc_channel_setup_dt(&adc_channels[i]);
		if (err < 0) {
			printk("Could not setup channel #%d (%d)\n", i, err);
		}
	}

	while (1) {
		printk("ADC reading[%u]:\n", count++);
		for (size_t i = 0U; i < ARRAY_SIZE(adc_channels); i++) {
			int32_t val_mv;

			printk("- %s, channel %d: ",
			       adc_channels[i].dev->name,
			       adc_channels[i].channel_id);

			(void)adc_sequence_init_dt(&adc_channels[i], &sequence);

			err = adc_read(adc_channels[i].dev, &sequence);
			if (err < 0) {
				printk("Could not read (%d)\n", err);
				continue;
			}

			/*
			 * If using differential mode, the 16 bit value
			 * in the ADC sample buffer should be a signed 2's
			 * complement value.
			 */
			if (adc_channels[i].channel_cfg.differential) {
				val_mv = (int32_t)((int16_t)buf);
			} else {
				val_mv = (int32_t)buf;
			}
			printk("%"PRId32, val_mv);
			err = adc_raw_to_millivolts_dt(&adc_channels[i],
						       &val_mv);
			/* conversion to mV may not be supported, skip if not */
			if (err < 0) {
				printk(" (value in mV not available)\n");
			} else {
				printk(" = %"PRId32" mV\n", val_mv);
			}
		}

		k_sleep(K_MSEC(1000));
	}
}




#if 1
K_THREAD_DEFINE(hmc_id, STACKSIZE, hmc_thread, NULL, NULL, NULL,
		PRIORITY, 0, 0);
K_THREAD_DEFINE(wifi_id, STACKSIZE, wifi_thread, NULL, NULL, NULL,
		PRIORITY, 0, 0);
K_THREAD_DEFINE(adc_id, STACKSIZE, adc_thread, NULL, NULL, NULL,
		PRIORITY, 0, 0);
#endif
```

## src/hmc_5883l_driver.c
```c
#include "hmc_5883l_driver.h"

#include <stddef.h>
#include <stdint.h>
#include <string.h>

// Public functions ==============================================================

int hmc_driverInit( hmc_5883l_driver_t* driver, void* instance, 
                        int (*read) (hmc_5883l_driver_t*, uint8_t*, uint8_t),
                        int (*write)(hmc_5883l_driver_t*, uint8_t*, uint8_t))
{
	if (driver == NULL || instance == NULL || read == NULL || write == NULL)
		return -1;

	driver->instance = instance;
	driver->read = read;
	driver->write = write;

	memset(driver->registers, 0, eHMC5883L_MAX_REGISTERS);

	return 0;
}


int hmc_configureContinuosMode(hmc_5883l_driver_t* driver)
{
	uint8_t hmc_command[2];

	// Write CRA (00) – send 0x3C 0x00 0x70 (8-average, 15 Hz default, normal measurement)
	hmc_command[0] = eHMC5883L_REG_CONFIG_A;
	hmc_command[1] = 0x70;

	if (driver->write(driver, hmc_command, sizeof(hmc_command)) != 0)
		return -1;

	// Write CRB (01) – send 0x3C 0x01 0xA0 (Gain=5, or any other desired gain)
	hmc_command[0] = eHMC5883L_REG_CONFIG_B;
	hmc_command[1] = 0xE0;

	if (driver->write(driver, hmc_command, sizeof(hmc_command)) != 0) 
		return -1;

	// Write Mode (02) – send 0x3C 0x02 0x00 (Continuous-measurement mode)
	hmc_command[0] = eHMC5883L_REG_MODE;
	hmc_command[1] = 0x00;

	if (driver->write(driver, hmc_command, sizeof(hmc_command)) != 0)
		return -1;
	
	return 0;
}


uint16_t hmc_readX_raw(hmc_5883l_driver_t* driver)
{
	uint8_t hmc_command = eHMC5883L_REG_DATA_OUTPUT_X_MSB;
	driver->write(driver, &hmc_command, sizeof(hmc_command));

	driver->read(driver, &driver->registers[eHMC5883L_REG_DATA_OUTPUT_X_MSB], 2);

	return (uint16_t) driver->registers[eHMC5883L_REG_DATA_OUTPUT_X_MSB] << 8 | driver->registers[eHMC5883L_REG_DATA_OUTPUT_X_LSB];
}


uint16_t hmc_readY_raw(hmc_5883l_driver_t* driver)
{
	uint8_t hmc_command = eHMC5883L_REG_DATA_OUTPUT_Y_MSB;
	driver->write(driver, &hmc_command, sizeof(hmc_command));

	driver->read(driver, &driver->registers[eHMC5883L_REG_DATA_OUTPUT_Y_MSB], 2);

	return (uint16_t) driver->registers[eHMC5883L_REG_DATA_OUTPUT_Y_MSB] << 8 | driver->registers[eHMC5883L_REG_DATA_OUTPUT_Y_LSB];
}


uint16_t hmc_readZ_raw(hmc_5883l_driver_t* driver)
{
	uint8_t hmc_command = eHMC5883L_REG_DATA_OUTPUT_Z_MSB;
	driver->write(driver, &hmc_command, sizeof(hmc_command));

	driver->read(driver, &driver->registers[eHMC5883L_REG_DATA_OUTPUT_Z_MSB], 2);

	return (uint16_t) driver->registers[eHMC5883L_REG_DATA_OUTPUT_Z_MSB] << 8 | driver->registers[eHMC5883L_REG_DATA_OUTPUT_Z_LSB];
}


int hmc_readX(hmc_5883l_driver_t* driver)
{
	int x;
	uint16_t rawx = hmc_readX_raw(driver);

	x = (int) rawx;

	return x;
}


int hmc_readY(hmc_5883l_driver_t* driver)
{
	int y;
	uint16_t rawy = hmc_readY_raw(driver);

	y = (int) rawy;

	return y;
}


int hmc_readZ(hmc_5883l_driver_t* driver)
{
	int z;
	uint16_t rawz = hmc_readZ_raw(driver);

	z = (int) rawz;

	return z;
}
```

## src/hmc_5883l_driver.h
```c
#ifndef __HMC_5883L_DRIVER_H__
#define __HMC_5883L_DRIVER_H__

#include <stdbool.h>
#include <stdint.h>
#include <stddef.h>

// Macros ==========================================================

/* I2C device address */
#define HMC5883L_I2C_ADDR	0x1E

// Data types ======================================================
/* Hmc internal registers */
enum hmc_5883l_Registers
{
    eHMC5883L_REG_CONFIG_A,
    eHMC5883L_REG_CONFIG_B,
    eHMC5883L_REG_MODE,
    eHMC5883L_REG_DATA_OUTPUT_X_MSB,
    eHMC5883L_REG_DATA_OUTPUT_X_LSB,
    eHMC5883L_REG_DATA_OUTPUT_Z_MSB,
    eHMC5883L_REG_DATA_OUTPUT_Z_LSB,
    eHMC5883L_REG_DATA_OUTPUT_Y_MSB,
    eHMC5883L_REG_DATA_OUTPUT_Y_LSB,
    eHMC5883L_REG_STATUS,
    eHMC5883L_REG_ID_A,
    eHMC5883L_REG_ID_B,
    eHMC5883L_REG_ID_C,
    eHMC5883L_MAX_REGISTERS
};

/* Driver data type */
typedef struct hmc_5883l_driver_s hmc_5883l_driver_t;
struct hmc_5883l_driver_s
{
    void*   instance;
    uint8_t registers[eHMC5883L_MAX_REGISTERS];

    int (*read) (hmc_5883l_driver_t*, uint8_t*, uint8_t);
    int (*write)(hmc_5883l_driver_t*, uint8_t*, uint8_t);
};

// Public API ======================================================

/// \brief Initializes i2c driver.
/// \param driver hmc driver structure pointer.
/// \param instance pointer to hardware handler instance.
/// \param read callback to read function.
/// \param write callback to write function.
/// \retval 0 if initialization was success and less than 0 otherwise.
int hmc_driverInit( hmc_5883l_driver_t* driver, void* instance, 
                        int (*read) (hmc_5883l_driver_t*, uint8_t*, uint8_t),
                        int (*write)(hmc_5883l_driver_t*, uint8_t*, uint8_t));


/// \brief Configures hmc device in continues mode.
/// \param driver hmc driver structure pointer.
/// \retval 0 if success, less than 0 if error.
int hmc_configureContinuosMode(hmc_5883l_driver_t* driver);


/// \brief Reads hmc X field component.
/// \param driver hmc driver structure pointer.
/// \retval Raw data containing X field component raw value.
uint16_t hmc_readX_raw(hmc_5883l_driver_t* driver);


/// \brief Reads hmc Y field component.
/// \param driver hmc driver structure pointer.
/// \retval Raw data containing Y field component raw value.
uint16_t hmc_readY_raw(hmc_5883l_driver_t* driver);


/// \brief Reads hmc Z field component.
/// \param driver hmc driver structure pointer.
/// \retval Raw data containing Z field component raw value.
uint16_t hmc_readZ_raw(hmc_5883l_driver_t* driver);


/// \brief Reads hmc X field component.
/// \param driver hmc driver structure pointer.
/// \retval Raw data containing X field component value.
int hmc_readX(hmc_5883l_driver_t* driver);


/// \brief Reads hmc Y field component.
/// \param driver hmc driver structure pointer.
/// \retval Raw data containing Y field component value.
int hmc_readY(hmc_5883l_driver_t* driver);


/// \brief Reads hmc Z field component.
/// \param driver hmc driver structure pointer.
/// \retval Raw data containing Z field component value.
int hmc_readZ(hmc_5883l_driver_t* driver);


// Initialization Macros =============================================

#define HMC_5883L_DRIVER_INIT_DEFAULT { \
    .instance = NULL,                   \
    .registers = {0},                   \
    .read = NULL,                       \
    .write = NULL                       \
}

#endif
```
